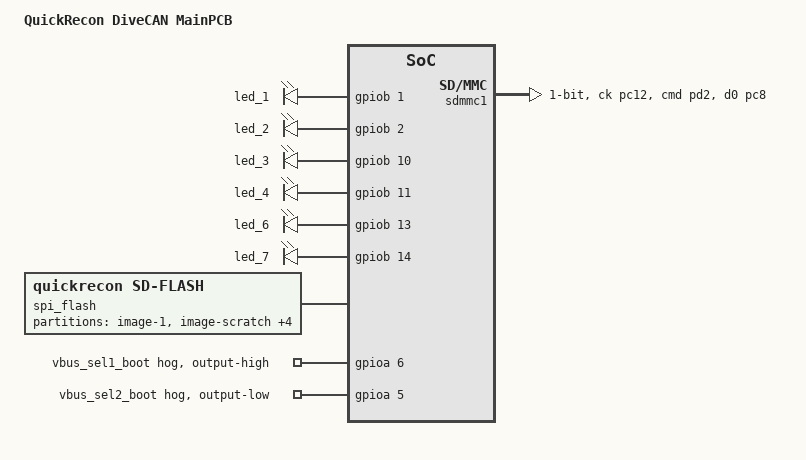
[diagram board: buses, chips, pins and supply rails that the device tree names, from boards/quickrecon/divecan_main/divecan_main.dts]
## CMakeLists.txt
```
cmake_minimum_required(VERSION 3.20.0)

set(DTS_ROOT ${CMAKE_CURRENT_SOURCE_DIR})

# Always-on GCC static analysis (-fanalyzer). Must be set before find_package(Zephyr).
# Analyzer false positives in CMSIS/HAL inline asm and Zephyr internals are demoted
# from -Werror to plain warnings; see COMPROMISE.md for the full list and rationale.
# Disabled on native_sim: host toolchain path doesn't populate GCC_COMPILER_VERSION
# before the SCA check runs, causing a false version-too-old error. Match the
# whole native_sim family (e.g. native_sim/native/64, required on aarch64 hosts),
# not just the bare "native_sim" string.
if(NOT BOARD MATCHES "native_sim")
    set(ZEPHYR_SCA_VARIANT gcc)
endif()
set(GCC_SCA_OPTS
    -Wno-error=analyzer-shift-count-overflow
    -Wno-error=analyzer-out-of-bounds
    -Wno-error=analyzer-null-dereference
    -Wno-error=analyzer-malloc-leak
    -Wno-error=analyzer-possible-null-dereference
    -Wno-error=analyzer-too-complex
    -Wno-error=analyzer-use-of-uninitialized-value
    -Wno-error=analyzer-infinite-loop
    -Wno-error=analyzer-deref-before-check
    -Wno-error=analyzer-allocation-size
    -Wno-error=analyzer-tainted-array-index
    -Wno-error=analyzer-tainted-offset
)

# Optional out-of-tree proprietary modules. Closed-source Zephyr modules that
# must never live in this tree are dropped into proprietary/<name>/ (git-ignored
# except the pointer doc — see proprietary/README.md). Any such module that
# supplies a zephyr/module.yml is discovered and wired in HERE (inside the app
# image's own CMakeLists, before its find_package) so it stays image-local: the
# MCUBoot child image runs its own find_package and never pulls it in. Never
# pass EXTRA_ZEPHYR_MODULES on the command line / env / cache — that would leak
# the module into the bootloader image.
#
# This is the generic hook retained for future proprietary subsystems. A module
# that a variant can *request* should follow the WANT_<FEATURE> / <FEATURE>
# Kconfig pattern (the variant sets CONFIG_WANT_<FEATURE>=y; the module defines
# the implementation symbol gated on its own devicetree node) and add its own
# "requested but unavailable" FATAL_ERROR check after find_package() below.
file(GLOB proprietary_module_manifests
     ${CMAKE_CURRENT_SOURCE_DIR}/proprietary/*/zephyr/module.yml)
foreach(module_manifest ${proprietary_module_manifests})
    get_filename_component(module_dir ${module_manifest} DIRECTORY) # .../<name>/zephyr
    get_filename_component(module_dir ${module_dir} DIRECTORY)      # .../<name>
    list(APPEND EXTRA_ZEPHYR_MODULES ${module_dir})
endforeach()

# The raw SD-to-flash adapter is shared by the application and MCUBoot on the
# DiveCAN MainPCB.  Keep it as a regular Zephyr module so each image gets the
# same flash semantics and devicetree binding; its Kconfig symbol remains off
# on boards without a quickrecon,sd-flash node.
list(APPEND EXTRA_ZEPHYR_MODULES
     ${CMAKE_CURRENT_SOURCE_DIR}/drivers/sd_flash)

# Required patches to the west-managed Zephyr tree, applied at configure time
# (idempotent, content-checked). The I2C patch backports the upstream STM32
# combined controller/target race handling to the pinned 4.4.1 release. The
# SPI-NOR fixes prevent wrong-address erases and unbounded WIP polling. A tree
# where a required patch is missing AND cannot be applied fails the build
# loudly. This runs before find_package so the sysbuild MCUBoot image also
# compiles the patched source.
set(_zephyr_tree "$ENV{ZEPHYR_BASE}")
if(NOT _zephyr_tree)
    execute_process(COMMAND west topdir
                    WORKING_DIRECTORY ${CMAKE_CURRENT_SOURCE_DIR}
                    OUTPUT_VARIABLE _west_topdir
                    OUTPUT_STRIP_TRAILING_WHITESPACE
                    RESULT_VARIABLE _west_rc ERROR_QUIET)
    if(_west_rc EQUAL 0)
        execute_process(COMMAND west config zephyr.base
                        WORKING_DIRECTORY ${CMAKE_CURRENT_SOURCE_DIR}
                        OUTPUT_VARIABLE _west_zephyr_base
                        OUTPUT_STRIP_TRAILING_WHITESPACE
                        RESULT_VARIABLE _west_base_rc ERROR_QUIET)
        if(_west_base_rc EQUAL 0)
            if(IS_ABSOLUTE "${_west_zephyr_base}")
                set(_zephyr_tree "${_west_zephyr_base}")
            else()
                set(_zephyr_tree "${_west_topdir}/${_west_zephyr_base}")
            endif()
        endif()
    endif()
endif()
if(_zephyr_tree AND EXISTS "${_zephyr_tree}/drivers/i2c/i2c_stm32_v2.c")
    file(READ "${_zephyr_tree}/drivers/i2c/i2c_stm32_v2.c" _i2c_stm32_src)
    string(FIND "${_i2c_stm32_src}"
           "i2c_stm32_target_preempt_controller_event" _i2c_race_marker)
    if(_i2c_race_marker EQUAL -1)
        set(_i2c_race_patch
            ${CMAKE_CURRENT_SOURCE_DIR}/patches/zephyr-i2c-stm32-controller-target-race.patch)
        execute_process(COMMAND git -C "${_zephyr_tree}" apply "${_i2c_race_patch}"
                        RESULT_VARIABLE _i2c_patch_rc
                        ERROR_VARIABLE _i2c_patch_err)
        if(NOT _i2c_patch_rc EQUAL 0)
            message(FATAL_ERROR
                "Zephyr STM32 I2C controller/target race patch is NOT applied "
                "and auto-apply failed (${_i2c_patch_err}). Building without "
                "it can route an own-address match through controller handling "
                "and panic in i2c_stm32_target_event(). Apply "
                "${_i2c_race_patch} to ${_zephyr_tree} (rebase it if the "
                "Zephyr revision changed).")
        endif()
        message(STATUS
            "Applied Zephyr STM32 I2C controller/target race patch to ${_zephyr_tree}")
    endif()
elseif(NOT BOARD MATCHES "native_sim")
    message(WARNING "Could not locate the Zephyr STM32 I2C driver to verify "
                    "the required controller/target race patch — do not ship "
                    "this build unverified.")
endif()

if(_zephyr_tree AND EXISTS "${_zephyr_tree}/drivers/flash/spi_nor.c")
    file(READ "${_zephyr_tree}/drivers/flash/spi_nor.c" _spi_nor_src)
    string(FIND "${_spi_nor_src}" "spi_nor_erase_opcode_4b" _patch_marker)
    if(_patch_marker EQUAL -1)
        set(_spi_nor_patch
            ${CMAKE_CURRENT_SOURCE_DIR}/patches/zephyr-spi-nor-4byte-erase-opcode.patch)
        execute_process(COMMAND git -C "${_zephyr_tree}" apply "${_spi_nor_patch}"
                        RESULT_VARIABLE _patch_rc ERROR_VARIABLE _patch_err)
        if(NOT _patch_rc EQUAL 0)
            message(FATAL_ERROR
                "zephyr spi_nor 4-byte erase-opcode patch is NOT applied and "
                "auto-apply failed (${_patch_err}). Building without it produces "
                "firmware that erases the wrong NOR locations. Apply "
                "${_spi_nor_patch} to ${_zephyr_tree} (rebase it if the zephyr "
                "revision changed).")
        endif()
        message(STATUS "Applied zephyr spi_nor 4-byte erase-opcode patch to ${_zephyr_tree}")
    endif()
    # Second patch: bound the WIP status poll with a timeout. Without it a
    # transient SPI glitch that leaves the status stuck WIP=1 busy-spins forever
    # and the IWDG resets the MCU mid erase/program (0xF278 mass erase never
    # reaches NVS; factory restore leaves slot1 incomplete). Re-read the source —
    # the 4-byte patch above may have just modified it.
    file(READ "${_zephyr_tree}/drivers/flash/spi_nor.c" _spi_nor_src2)
    string(FIND "${_spi_nor_src2}" "wip_deadline" _wip_marker)
    if(_wip_marker EQUAL -1)
        set(_wip_patch
            ${CMAKE_CURRENT_SOURCE_DIR}/patches/zephyr-spi-nor-wip-timeout.patch)
        execute_process(COMMAND git -C "${_zephyr_tree}" apply "${_wip_patch}"
                        RESULT_VARIABLE _wip_rc ERROR_VARIABLE _wip_err)
        if(NOT _wip_rc EQUAL 0)
            message(FATAL_ERROR
                "zephyr spi_nor WIP-poll timeout patch is NOT applied and "
                "auto-apply failed (${_wip_err}). Without it a stuck SPI-NOR "
                "status poll hangs until the IWDG resets the MCU mid "
                "erase/program. Apply ${_wip_patch} to ${_zephyr_tree} (rebase "
                "it if the zephyr revision changed).")
        endif()
        message(STATUS "Applied zephyr spi_nor WIP-poll timeout patch to ${_zephyr_tree}")
    endif()

elseif(NOT BOARD MATCHES "native_sim")
    message(WARNING "Could not locate the Zephyr tree to verify required "
                    "SPI-NOR patches — do not ship this build unverified.")
endif()

if(_zephyr_tree AND EXISTS "${_zephyr_tree}/subsys/fs/fcb/fcb.c")
    file(READ "${_zephyr_tree}/include/zephyr/fs/fcb.h" _fcb_hdr)
    string(FIND "${_fcb_hdr}" "FCB_FLAGS_INIT_SKIP_WALK" _fcb_marker)
    if(_fcb_marker EQUAL -1)
        set(_fcb_patch
            ${CMAKE_CURRENT_SOURCE_DIR}/patches/zephyr-fcb-init-skip-entry-walk.patch)
        execute_process(COMMAND git -C "${_zephyr_tree}" apply "${_fcb_patch}"
                        RESULT_VARIABLE _fcb_rc ERROR_VARIABLE _fcb_err)
        if(NOT _fcb_rc EQUAL 0)
            message(FATAL_ERROR
                "Zephyr FCB init-skip-walk patch is NOT applied and auto-apply "
                "failed (${_fcb_err}). Without it the flash-log FCB mount does "
                "thousands of tiny SPI reads at boot, scaling boot time with "
                "log depth. Apply ${_fcb_patch} to ${_zephyr_tree}.")
        endif()
        message(STATUS "Applied Zephyr FCB init-skip-walk patch to ${_zephyr_tree}")
    endif()
endif()

if(_zephyr_tree AND EXISTS "${_zephyr_tree}/subsys/kvss/nvs/nvs_priv.h")
    file(READ "${_zephyr_tree}/subsys/kvss/nvs/nvs_priv.h" _nvs_hdr)
    string(FIND "${_nvs_hdr}" "#ifndef NVS_BLOCK_SIZE" _nvs_marker)
    if(_nvs_marker EQUAL -1)
        set(_nvs_patch
            ${CMAKE_CURRENT_SOURCE_DIR}/patches/zephyr-nvs-block-size-override.patch)
        execute_process(COMMAND git -C "${_zephyr_tree}" apply "${_nvs_patch}"
                        RESULT_VARIABLE _nvs_rc ERROR_VARIABLE _nvs_err)
        if(NOT _nvs_rc EQUAL 0)
            message(FATAL_ERROR
                "Zephyr NVS block-size override patch is NOT applied and "
                "auto-apply failed (${_nvs_err}). Without it the NVS sector "
                "scans read 32 bytes per SPI transaction at boot. Apply "
                "${_nvs_patch} to ${_zephyr_tree}.")
        endif()
        message(STATUS "Applied Zephyr NVS block-size override patch to ${_zephyr_tree}")
    endif()
endif()

find_package(Zephyr REQUIRED HINTS $ENV{ZEPHYR_BASE})
project(divecan_firmware)

# Widen the NVS read/compare granule (default 32 B) so the boot-time sector
# scans over external SPI NOR amortise the per-transaction SPI framework
# overhead (32 reads per 4 KiB sector check instead of 128). Stack cost: one
# NVS_BLOCK_SIZE buffer per NVS read/compare/write frame (+96 B vs the 32 B
# default) on every NVS caller — main, divecan_rx (UDS settings saves), and
# the system workqueue (error-histogram periodic save). 256 was tried and
# CRASHED both settings-heavy HIL tests with STACK_CHK_FAIL on divecan_rx /
# sysworkq (run 31187089880); 128 halves the pressure and those two stacks
# also gained +256 B headroom each. Requires the nvs_priv.h #ifndef guard
# patch above.
zephyr_compile_definitions(NVS_BLOCK_SIZE=128)

target_sources(app PRIVATE
    src/main.c
    src/errors.c
    src/boot_history.c
    src/runtime_settings.c
    src/oxygen_cell_math.c
    src/oxygen_cell_channels.c
    src/consensus_subscriber.c
    src/calibration.c
    src/calibration_store.c
    src/hw_version.c
    src/power_math.c
    src/power_management.c
    src/heartbeat.c
    src/i2c_bus_lock.c
    src/external_flash.c
    src/storage_work_queue.c
    src/error_histogram.c
    src/firmware_confirm.c
    src/flash_mass_erase.c
    src/maintenance_arena.c
    src/device_current.c
)
target_sources_ifdef(CONFIG_ALARM app PRIVATE src/alarm.c)
target_sources_ifdef(CONFIG_POSEIDON_ACCESSORIES app PRIVATE
    src/poseidon_accessories.c)
# The paced thread-analyzer wrapper calls thread_analyzer_run(), which
# Zephyr only provides when CONFIG_THREAD_ANALYZER=y. That symbol has
# `depends on !ARCH_POSIX`, so on native_sim it is unavailable and the
# source must not be compiled. Guard accordingly.
target_sources_ifdef(CONFIG_THREAD_ANALYZER app PRIVATE
    src/thread_analyzer_paced.c)
target_sources_ifdef(CONFIG_FACTORY_IMAGE app PRIVATE src/factory_image.c)
target_sources_ifdef(CONFIG_FACTORY_IMAGE_BACKEND_FLASH app PRIVATE
    src/factory_image_backend_flash.c)
target_sources_ifdef(CONFIG_DIVECAN_OPTION_BYTES_CHECK app PRIVATE
    src/option_bytes.c)
target_sources_ifdef(CONFIG_DIVECAN_WATCHDOG app PRIVATE src/watchdog_feeder.c)
target_sources_ifdef(CONFIG_HAS_ANALOG_CELL app PRIVATE src/oxygen_cell_analog.c)
target_sources_ifdef(CONFIG_HAS_PRESSURE_TRANSDUCER app PRIVATE
    src/tank_pressure.c
    src/tank_pressure_math.c)
target_sources_ifdef(CONFIG_HAS_DIVEO2_CELL app PRIVATE src/oxygen_cell_diveo2.c)
target_sources_ifdef(CONFIG_HAS_O2S_CELL app PRIVATE src/oxygen_cell_o2s.c)

# PPO2 PID controller + solenoid fire timing — pure math is always built so
# UDS state-DID handlers can call ppo2_control_get_snapshot() unconditionally,
# but the threaded controller is only compiled in when a physical O2
# injection solenoid is present on the variant.
target_sources(app PRIVATE src/ppo2_control_math.c src/ppo2_control.c)
# PID autotune — always built (pure math + stubs); the threaded routine and its
# thread are gated on CONFIG_HAS_O2_SOLENOID inside the TU. Autotune ships with
# PID (no separate Kconfig): wherever PID control exists, autotune exists.
target_sources(app PRIVATE src/ppo2_autotune_math.c src/ppo2_autotune.c)
target_include_directories(app PRIVATE include)

# DiveCAN protocol + UDS/ISO-TP
target_sources(app PRIVATE
    src/divecan/divecan_channels.c
    src/divecan/divecan_send.c
    src/divecan/divecan_tx.c
    src/divecan/isotp.c
    src/divecan/isotp_tx_queue.c
    src/divecan/divecan_rx.c
    src/divecan/divecan_ppo2_math.c
    src/divecan/divecan_ppo2_tx.c
    src/divecan/uds/uds.c
    src/divecan/uds/uds_ota.c
    src/divecan/uds/uds_state_did.c
    src/divecan/uds/uds_settings.c
    src/divecan/uds/uds_log_push.c
)
# UDS log push as a Zephyr log backend (live RTT-over-UDS streaming).
# Depends on the flash log subsystem for the shared severity threshold
# accessor — the two backends together give us "persistent log on flash
# + live tail over UDS" with one runtime control DID.
target_sources_ifdef(CONFIG_FLASH_LOG app PRIVATE
    src/divecan/uds/uds_log_push_backend.c
)
target_include_directories(app PRIVATE src/divecan/include)
target_include_directories(app PRIVATE src)

# Flash log subsystem — two FCB instances, single writer thread,
# zbus listeners + RTT capture backend + UDS download path.
target_sources_ifdef(CONFIG_FLASH_LOG app PRIVATE
    src/flash_log/flash_log.c
    src/flash_log/flash_log_fastseek.c
    src/flash_log/flash_log_listeners.c
    src/flash_log/flash_log_backend.c
    src/flash_log/flash_log_index.c
    src/flash_log/flash_log_reader.c
    src/divecan/uds/uds_log_download.c
)
target_include_directories(app PRIVATE src/flash_log)

add_subdirectory(drivers/solenoid)
add_subdirectory(drivers/ads1x1x)
add_subdirectory_ifdef(CONFIG_GPIO_SIM drivers/gpio_sim)

# Build-time version string. We pass it in as an already-quoted string literal
# so the C code never has to stringify a token (avoids SonarCloud S958/S959/
# S960/S967/S968/M23_042/M23_212 firings on a STRINGIFY macro chain).
# Prefer `git describe`; fall back to "dev" outside a git checkout.
execute_process(
    COMMAND git -C ${CMAKE_CURRENT_SOURCE_DIR} describe --tags --always --dirty
    OUTPUT_VARIABLE APP_BUILD_VERSION_RAW
    OUTPUT_STRIP_TRAILING_WHITESPACE
    ERROR_QUIET
    RESULT_VARIABLE APP_BUILD_VERSION_RC
)
if(NOT APP_BUILD_VERSION_RC EQUAL 0 OR APP_BUILD_VERSION_RAW STREQUAL "")
    set(APP_BUILD_VERSION_RAW "dev")
endif()
target_compile_definitions(app PRIVATE
    APP_BUILD_VERSION_STR="${APP_BUILD_VERSION_RAW}"
)

# Keep a full commit identity for manifests and release provenance. git describe
# is intentionally shorter/human-facing and remains the firmware UI string.
execute_process(
    COMMAND git -C ${CMAKE_CURRENT_SOURCE_DIR} rev-parse HEAD
    OUTPUT_VARIABLE APP_BUILD_COMMIT_RAW
    OUTPUT_STRIP_TRAILING_WHITESPACE
    ERROR_QUIET
    RESULT_VARIABLE APP_BUILD_COMMIT_RC
)
if(NOT APP_BUILD_COMMIT_RC EQUAL 0 OR APP_BUILD_COMMIT_RAW STREQUAL "")
    set(APP_BUILD_COMMIT_RAW "${APP_BUILD_VERSION_RAW}")
endif()

# VERSION is the product release number and the source for MCUboot's image
# header version. Keep the independently-derived git identity above as the
# exact source revision. Both are emitted into test_manifest.json so HIL and
# release packaging can prove which numbered image and commit they exercised.
if(NOT DEFINED APP_VERSION_STRING OR APP_VERSION_STRING STREQUAL "")
    set(APP_RELEASE_VERSION_RAW "0.0.0")
else()
    set(APP_RELEASE_VERSION_RAW "${APP_VERSION_STRING}")
endif()

# Build-time variant string, derived from the selected variant conf
# (-DEXTRA_CONF_FILE=variants/<Name>.conf). Baked into the binary (served over
# UDS DID 0xF002) AND written into test_manifest.json below, both from this one
# value, so the HIL rig can assert the flashed variant matches the manifest it
# is qualifying against. Falls back to "dev" when no variant conf is selected.
set(APP_BUILD_VARIANT_RAW "dev")
if(DEFINED EXTRA_CONF_FILE AND EXTRA_CONF_FILE MATCHES "variants/([^/;]+)\\.conf")
    set(APP_BUILD_VARIANT_RAW "${CMAKE_MATCH_1}")
endif()
target_compile_definitions(app PRIVATE
    APP_BUILD_VARIANT_STR="${APP_BUILD_VARIANT_RAW}"
)

# App-only hardening flags (not applied to Zephyr kernel/drivers).
#
# Scope: this is an open-source, deliberately-hackable platform — there
# is no adversary, no secrets to protect, no fault-injection threat
# model. The only attack surface that matters is the one that exists
# anyway: software bugs, buffer overflows, uninitialised reads. We
# harden against those and ignore the rest.
#
# What's enabled:
#   -ftrivial-auto-var-init=pattern   catches uninit-read bugs by
#                                     filling locals with 0xAA
#   _FORTIFY_SOURCE=2 (via Kconfig)   runtime bounds checks on libc
#                                     string/mem ops when the dest
#                                     size is compile-time known
#   stack canaries (via Kconfig)      catch return-address smashing
#                                     from buffer overflows
#   -Wstack-usage=1305                static cap on per-function stack
#
# What's deliberately NOT enabled:
#   -fstack-clash-protection          mitigates unbounded stack growth
#                                     attack — architecturally impossible
#                                     here per NASA P10 (no recursion,
#                                     no VLAs, all loops fixed-bound)
#   -fharden-compares                 fault-injection defence — out of
#                                     scope per platform philosophy
#   -fharden-conditional-branches     same as above
#
target_compile_options(app PRIVATE
    -Wall
    -Wextra
    -Wwrite-strings
    -Wreturn-type
    -Wno-unused-parameter
    -Wno-vla
    -ftrivial-auto-var-init=pattern
    -fstack-usage
    -std=gnu23
)
target_cc_option(app PRIVATE -Wstack-usage=1305)

# Integration test shim (native_sim only)
target_sources_ifdef(CONFIG_INTEGRATION_TEST_SHIM app PRIVATE
    tests/integration/src/test_shim.c
    tests/integration/src/test_shim_uart.c
    tests/integration/src/test_shim_adc.c
    tests/integration/src/test_shim_gpio.c
    tests/integration/src/test_shim_shared.c
)
# Host-side adapter — compiled into the native_simulator runner so it
# can use raw Linux/glibc headers without colliding with Zephyr's POSIX
# shims.  Provides shared memory wrappers.
if(CONFIG_INTEGRATION_TEST_SHIM)
    target_sources(native_simulator INTERFACE
        ${CMAKE_CURRENT_SOURCE_DIR}/tests/integration/src/test_shim_socket_adapt.c)
    target_link_options(native_simulator INTERFACE "-lrt")
endif()

# --- HIL test manifest -------------------------------------------------------
# Emit a machine-readable description of this binary's compile-time config
# (cells/power/solenoids/control + CAN bitrate) so the test rig (divecan_rig)
# can self-configure and select the tests relevant to the flashed binary.
# Reads the resolved Kconfig (.config) + devicetree; both exist by build time.
add_custom_command(
    TARGET app POST_BUILD
    COMMAND ${PYTHON_EXECUTABLE}
            ${CMAKE_CURRENT_SOURCE_DIR}/scripts/gen_test_manifest.py
            --config ${CMAKE_BINARY_DIR}/zephyr/.config
            --dt-header ${CMAKE_BINARY_DIR}/zephyr/include/generated/zephyr/devicetree_generated.h
            --variant ${APP_BUILD_VARIANT_RAW}
            --version ${APP_RELEASE_VERSION_RAW}
            --commit ${APP_BUILD_COMMIT_RAW}
            --out ${CMAKE_BINARY_DIR}/zephyr/test_manifest.json
    BYPRODUCTS ${CMAKE_BINARY_DIR}/zephyr/test_manifest.json
    COMMENT "Emitting HIL test_manifest.json from resolved Kconfig + devicetree"
    VERBATIM
)
```

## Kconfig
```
mainmenu "DiveCAN Firmware"

rsource "drivers/solenoid/Kconfig"
rsource "drivers/ads1x1x/Kconfig"
rsource "src/Kconfig"

source "Kconfig.zephyr"
```

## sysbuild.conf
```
# Sysbuild configuration for DiveCAN firmware with MCUBoot.
#
# See ARCHITECTURE.md and the OTA plan for design rationale. Key
# choices captured here:
#
# - MCUBoot is the bootloader (slot0 = internal flash 220 KiB;
#   slot1 + scratch + factory use the board's external flash-compatible
#   device: SPI NOR on Jr, raw SD on MainPCB).
# - Swap-using-scratch — the scratch partition gives clean failure
#   isolation: slot0 is untouched until each swap step completes.
#   Higher write amplification than swap-using-move but easier to
#   reason about under power loss.
# - No private-key signing. SHA-256 integrity only. This is an open
#   platform — anyone can build and flash without holding a signing
#   key. Per-image hash verification (`bootutil_img_validate`) still
#   catches corruption pre-swap.

SB_CONFIG_BOOTLOADER_MCUBOOT=y
SB_CONFIG_MCUBOOT_MODE_SWAP_SCRATCH=y
SB_CONFIG_BOOT_SIGNATURE_TYPE_NONE=y
SB_CONFIG_BOOT_SIGNATURE_KEY_FILE=""

# Emit a single merged.hex containing bootloader + signed app for
# convenient `west flash` / probe-rs / openocd flashing.
SB_CONFIG_MERGED_HEX_FILES=y
```

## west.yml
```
manifest:
  remotes:
    - name: zephyrproject-rtos
      url-base: https://github.com/zephyrproject-rtos

  projects:
    - name: zephyr
      remote: zephyrproject-rtos
      # Pinned to the Zephyr 4.4.1 release revision so CI
      # analyzes exactly what local builds and HIL testing run against.
      # Bump deliberately: update the local checkout, re-run the native +
      # HIL suites, then move this pin to match.
      revision: 1f6485eca25431b5ff27ce9a754218c9e559bbbb
      # Keep west-managed repositories out of the application repository's
      # visible top-level tree. The prefix applies to Zephyr itself and every
      # project imported by Zephyr's manifest (modules, MCUboot, tools, etc.).
      # Changing it requires pristine builds because CMake caches these paths.
      import:
        path-prefix: .west-projects

  self:
    path: app
```

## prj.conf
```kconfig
CONFIG_PRINTK=y
CONFIG_GPIO=y
CONFIG_CONSOLE=y
CONFIG_USE_SEGGER_RTT=y
CONFIG_RTT_CONSOLE=y

# Hardening (applied globally — Zephyr + app)
# Entropy/RNG disabled — entropy_stm32_rng_init asserts during init on Jr
# hardware (PC=assert_post_action, LR=entropy_stm32.c:862, reason=
# K_ERR_KERNEL_PANIC). Just commenting out CONFIG_ENTROPY_GENERATOR is
# NOT enough: the STM32 RNG driver's Kconfig auto-enables when the DT
# rng node is "okay", which selects ENTROPY_HAS_DRIVER which pulls in
# ENTROPY_GENERATOR. The override below forces the driver off so the
# init function never runs. Root cause is likely PLL Q clock config
# for CLK48 mux — leaves the RNG without a clock, dev->data deref
# faults. TODO: revisit clock setup so we can re-enable HW entropy.
# CONFIG_ENTROPY_GENERATOR=y
CONFIG_ENTROPY_STM32_RNG=n
CONFIG_FORTIFY_SOURCE_RUN_TIME=y
CONFIG_HW_STACK_PROTECTION=y
CONFIG_COMPILER_WARNINGS_AS_ERRORS=y
CONFIG_OVERRIDE_FRAME_POINTER_DEFAULT=y

# Stack canaries — guard word at the bottom of every function's stack
# frame, checked at epilogue. Catches return-address smashing from
# buffer overflows (the dominant software-bug failure mode in C). The
# _STRONG variant covers any function with a local array OR taking
# the address of a local, which is what we want — bog-standard
# _REGULAR only protects functions with char buffers ≥8 bytes and
# misses most real overflow targets. Canary seed comes from a build-
# time random word via the SDK; not cryptographically strong but the
# threat model here is software bugs, not adversarial bypass.
CONFIG_STACK_CANARIES=y
CONFIG_STACK_CANARIES_STRONG=y

# Hardware FPU — DELIBERATELY OFF, measured 2026-07. The M4F single-precision
# FPU looks free but is not: safe multi-thread FP requires CONFIG_FPU_SHARING
# (float math runs in PID, consensus, cell, and cal threads), and on this
# build that costs ~3.2 KB of RAM — 64 B of callee-saved FP context appended
# to every struct k_thread (~22 threads) plus the MPU stack guard widening
# from 32 B to 128 B per stack for lazy-stacking overlap. The Poseidon build
# sits at ~99.8% RAM, so enabling it overflowed the region by 3,184 B for a
# ~2.5 KB FLASH saving (single-precision softfloat elimination). Softfloat
# single is fast enough for the 100 ms control cadence. REVISIT if the
# thread count drops substantially (consolidation shrinks the per-thread
# tax) or if RAM headroom appears.
# CONFIG_FPU=y
# CONFIG_FPU_SHARING=y

# Link-time optimization — REJECTED 2026-07 on HIL A/B evidence, despite a
# −21.6 KB (−11%) app-image saving. With CONFIG_LTO=y (+
# CONFIG_ISR_TABLES_LOCAL_DECLARATION=y) the DUT reproducibly failed
# test_dut_services.py::test_factory_default_battery_threshold_matches_manifest:
# after the NVS-erase DID (0xF279) warm reboot the head came back NOT
# broadcasting PPO2 (UDS still answered; a cold power cycle recovered it).
# 3/3 fail with LTO, 3/3 pass on the byte-identical source tree without
# LTO, 3/3 pass on the pre-change baseline. Root cause not isolated (LTO
# inlining/reordering exposing a latent init race, or a miscompile) — an
# unexplained behavioral delta is disqualifying on a life-support device.
# Re-attempt only WITH a root cause. Repro: seed a non-default battery
# setting, programming session, write 0xF279=0x01, wait for the PPO2
# broadcast to resume (it doesn't). If re-attempted, remember: size(1)
# misreports LTO rodata as `data` (use the linker region table) and
# -fstack-usage/.su static WCS numbers degrade under LTO.
# CONFIG_LTO=y
# CONFIG_ISR_TABLES_LOCAL_DECLARATION=y

# Main thread stack — kept at 2048 after a 1024 trim caused a
# K_ERR_STACK_CHK_FAIL canary trip on real hardware. Static WCS came
# back "unbounded" for main because settings/MCUBoot/SPI inits hit
# function-pointer call paths the analyzer can't trace; runtime
# evidence is the only reliable bound. Revisit only with INIT_STACKS
# high-water-mark data from a real boot.
CONFIG_MAIN_STACK_SIZE=2048

# Assertions (kept in production — controlled reboot over undefined behavior)
CONFIG_ASSERT=y
CONFIG_ASSERT_VERBOSE=y

# Printf/cbprintf size trims — app code has no %lld/%llu and no
# LOG_DBG callsites (verified via grep), so the FULL_INTEGRAL formatter
# table and the function-name prefix infrastructure are dead weight in
# this binary. Switching to REDUCED_INTEGRAL keeps %d/%u/%x/%s/%c/%p
# but drops the long-long path. PICOLIBC_IO_LONG_LONG mirrors the same
# trim on the picolibc side for stdio.
# Saves ~1-2 KB FLASH each. Revisit if any new LOG_x site needs %lld.
CONFIG_CBPRINTF_FULL_INTEGRAL=n
CONFIG_CBPRINTF_REDUCED_INTEGRAL=y
CONFIG_PICOLIBC_IO_LONG_LONG=n
CONFIG_LOG_FUNC_NAME_PREFIX_DBG=n

# Logging — deferred mode. Buffer reduced from 2 KB to 1 KB to free
# RAM; the processing thread runs at high priority (3) so the buffer
# drains quickly and a smaller staging area is fine for the bursts
# we actually see. Watch dropped_cnt in the RTT log_core stats — if
# it climbs noticeably under real workloads, bump back to 2048.
CONFIG_LOG=y
CONFIG_LOG_BUFFER_SIZE=1024
CONFIG_LOG_PROCESS_THREAD_PRIORITY=3
# RTT up-buffer at 2 KB. Both MCUBoot and this app place
# SEGGER_RTT_SECTION_CUSTOM at RAM base, then lay it out as
# _acUpBuffer + _acDownBuffer + _SEGGER_RTT. The buffer size must
# match between binaries or the control block ends up at different
# addresses — openocd attaches to whichever address it finds first
# (MCUBoot's, since its address is lower) and stays locked there
# after MCUBoot chainloads, so the app's logs vanish into a control
# block that openocd never reads. sysbuild/mcuboot.conf carries a
# matching CONFIG_SEGGER_RTT_BUFFER_SIZE_UP=2048 to keep both
# binaries' _SEGGER_RTT at the same address. Reduced from 4 KB to
# 4 KB to accommodate the boot-time preamble burst (~1.5 KB of
# `emit_startup_preamble` in src/main.c) on top of the regular
# pre-main and pre-host-attach LOG output (~1 KB of MCUBoot + early
# init lines). At 2 KB the preamble was being trimmed from the
# up-buffer before openocd could drain it, even with 50 ms per-line
# pacing. Verified against chip RTT capture. Costs +2 KB RAM (RTT
# section is in noinit; doesn't grow .bss). Must match
# sysbuild/mcuboot.conf so MCUBoot and app's _SEGGER_RTT control
# block end up at the same RAM address (see comment above).
CONFIG_SEGGER_RTT_BUFFER_SIZE_UP=4096

# Reboot
CONFIG_REBOOT=y

# IPC (zbus for decoupled inter-module communication)
CONFIG_ZBUS=y
CONFIG_ZBUS_MSG_SUBSCRIBER=y

# State Machine Framework — flat-only, no hierarchical / initial-transition support.
# See docs/STATE_MACHINES.md for the modules that use it.
CONFIG_SMF=y
# CONFIG_SMF_ANCESTOR_SUPPORT is not set
# CONFIG_SMF_INITIAL_TRANSITION is not set

# ---- MCUBoot + OTA support ----
# Build app as an MCUBoot-compatible image (slot0). Sysbuild also
# pulls in the bootloader as a child image — see sysbuild.conf and
# sysbuild/mcuboot.conf.
CONFIG_BOOTLOADER_MCUBOOT=y

# Bootutil library — exposes boot_swap_type, boot_read_bank_header,
# bootutil_img_validate to the application so it can interrogate
# MCUBoot state and pre-validate slot1 before triggering activation.
CONFIG_MCUBOOT_BOOTUTIL_LIB=y

# Image manager API — boot_request_upgrade, boot_write_img_confirmed,
# boot_is_img_confirmed.
CONFIG_MCUBOOT_IMG_MANAGER=y
CONFIG_IMG_MANAGER=y

# Buffered flash writer for the OTA RX path. This is a write-coalescing
# buffer, NOT an erase buffer — flash_img_buffered_write() accumulates
# incoming UDS payload bytes and flushes when full. Sector erase is
# handled internally by the DFU subsystem at sector boundaries based on
# the running write offset, independent of the buffer size. Only
# constraint: must be >= the flash write block size. 1024 amortises the
# external-device transaction overhead while costing only 1 KB of RAM vs. the
# previous 4 KB.
CONFIG_IMG_BLOCK_BUF_SIZE=1024
CONFIG_STREAM_FLASH=y
CONFIG_FLASH_MAP=y

# SHA-256 walk over a flash area — used by the UDS-OTA pre-activation
# pipeline to verify slot1 matches the SHA-256 TLV embedded in the
# image trailer before boot_request_upgrade() is allowed to run.
CONFIG_IMG_ENABLE_IMAGE_CHECK=y

# ---- Analog oxygen cells (external ADS1115 ADCs) ----
# Use the board-local multi-channel ADS1X1X driver (drivers/ads1x1x) instead of
# the upstream single-channel one. The upstream driver only supports channel_id
# 0, so a second analog cell sharing one ADS1115 (e.g. AIN2-AIN3) silently never
# reads. The fork stores per-channel MUX config and programs it per conversion.
# Disable the in-tree driver so only one instantiates the ti,ads1115 nodes.
CONFIG_ADC=y
CONFIG_ADC_ADS1X1X=n
CONFIG_ADC_ADS1X1X_LOCAL=y

# ---- Settings + NVS on external storage ----
# Storage partition (label "storage") lives at the top of the board's
# 64 MB external flash device — SPI NOR on Jr or raw SD on MainPCB.
# Zephyr's settings subsystem discovers it through storage_partition.
CONFIG_FLASH=y
CONFIG_SETTINGS=y
CONFIG_SETTINGS_NVS=y
CONFIG_NVS=y

# The board flash driver must expose 4 KB logical erase pages so the 32 KB
# settings partition mounts as eight NVS sectors. Jr configures this through
# SPI_NOR_FLASH_LAYOUT_PAGE_SIZE; the MainPCB SD wrapper declares the same
# geometry in devicetree.

# Factory-image copy chunk size — read/write loop only, not erase-related.
# 1 KB gives 220 loop iterations across the 220 KB slot at ~hundreds of
# microseconds per SPI read+write; the watchdog feeds inside the loop.
# Was 4 KB by default; the "matches sector erase" rationale in the
# original Kconfig help is wrong — the bulk erase happens before the
# copy loop starts.
CONFIG_FACTORY_IMAGE_CHUNK_SIZE=1024

# ---- Flash log (FCB-based dive log) ----
# Two parallel FCB instances on external flash — telemetry FCB
# for structured records and text FCB for LOG_x capture. Each
# declares 100 × 64 KiB logical sectors (block-erase). See
# docs/FLASH_LOG.md and src/flash_log/.
CONFIG_FLASH_LOG=y
CONFIG_FCB=y
CONFIG_FCB_ALLOW_FIXED_ENDMARKER=y
# Used to stamp reset_cause in the BOOT_MARKER entry
CONFIG_HWINFO=y

# ---- Thread stack instrumentation (belt and braces) ----
# Two complementary tools share one goal — keeping stack budgets honest:
#   - Static: scripts/stack_analysis.sh walks .su + RTL dumps to compute
#     worst-case stack per function (upper bounds, derived at build time).
#   - Runtime: INIT_STACKS fills each stack with a sentinel pattern at spawn
#     time so targeted high-water-mark builds can count untouched bytes.
# The always-on paced thread analyzer was removed from production builds to
# fund the UDS RX stack margin found necessary by HIL crash-injection testing.
# Re-enable only in a temporary measurement build.
# CONFIG_THREAD_ANALYZER is not set
# CONFIG_THREAD_ANALYZER_USE_LOG is not set
# AUTO mode disabled — its tight emission loop floods 40+ LOG_INF
# back-to-back from a single thread tick, overflowing the 1 KB
# deferred log buffer (LOG_MODE_OVERFLOW=y evicts oldest, so the
# first half of the dump disappears). We run our own paced wrapper
# in src/thread_analyzer_paced.c that calls thread_analyzer_run()
# with a callback that LOG_INFs one thread, k_msleeps 50 ms to let
# the log subsystem drain, then proceeds. Same output, no drops.
# CONFIG_THREAD_ANALYZER_AUTO is not set
# Analyzer auto mode remains disabled; use src/thread_analyzer_paced.c only in
# deliberate measurement builds where CONFIG_THREAD_ANALYZER is re-enabled.
# CONFIG_THREAD_ANALYZER_AUTO_STACK_SIZE is not set
CONFIG_INIT_STACKS=y
CONFIG_THREAD_NAME=y
CONFIG_THREAD_STACK_INFO=y

# scripts/wcs.py static-WCS for fl_writer is ~336 B but the RUNTIME high-water was
# ~944-984 B (thread_analyzer / check_high_water) — the static tool under-counts the
# FCB/flash/spi_nor call depth, and the two ~100 B header+payload coalescing buffers
# (fl_write_entry_to_fcb + fl_write_telemetry_batch Pass B) used to sit on this stack,
# BOTH live at once on the Pass-1 chain (~200 B). Those are now a single shared static
# (fl_writer_scratch, 108 B) — the writer is the only thread on the FCB path and the
# passes run sequentially, so it is safe. -fstack-usage confirms the deepest chain
# dropped ~200 B (fl_batch_flush 216->112, fl_write_entry_to_fcb 168->72); since the
# flash/SPI tail is unchanged the runtime high-water drops by the same ~200 B, i.e.
# to ~760-790 B. Audited: NO unbounded items (no alloca/VLA/recursion). Kept at 1024
# (NOT reduced) on purpose: the rare fcb_rotate()/256 KiB sector-erase path is deeper
# than the normal-append sample and remains UNMEASURED, so 1024 preserves a strict
# margin gain on every path (~234 B normal, +200 B vs before on rotation) rather than
# trading it away. (NOT the #5 crash — that was cal_thread, see calibration.c.)
# Open validation: re-run scripts/check_high_water.py on hardware, ideally forcing a
# ring wrap, before reducing this. RAM cost of the static: +64 B (AP 144->80 B free).
CONFIG_FLASH_LOG_WRITER_STACK=1024

# ---- LPTIM kernel timebase (see divecan_jr.dts stm32_lp_tick_source) ----
# CONFIG_PM is required by STM32_LPTIM_TIMER. The board DTS deletes
# cpu-power-states, so PM never enters STOP on idle (WFI only): SWD stays
# attached and the CAN peripheral keeps receiving. LPTIM on LSI decouples
# kernel time from HCLK so boot_clock_boost() can switch SYSCLK safely.
CONFIG_PM=y

# The error-histogram periodic save runs NVS writes on the system workqueue;
# with the widened NVS_BLOCK_SIZE stack buffers the default 1024 B is too
# tight (STACK_CHK_FAIL family, run 31187089880). +256 B headroom.
CONFIG_SYSTEM_WORKQUEUE_STACK_SIZE=1280

# NVS lookup cache. Without it, settings_save_one() linearly scans the storage
# partition on every write: BENCH-MEASURED 8.4-8.6 s for the first write of a key
# after boot (reproducible across boots) and ~1.0-1.6 s steady-state, during which
# the head transmits NOTHING on DiveCAN -- PPO2 broadcasts included. With the cache
# the same writes cost 6-9 ms. Size matters and was measured, not guessed: 64 gives
# ~7 ms while 32 and 16 both sit at ~1.0 s, so do not shrink this to reclaim RAM
# without re-measuring.
CONFIG_NVS_LOOKUP_CACHE=y
CONFIG_NVS_LOOKUP_CACHE_SIZE=64

# Keep the ordinary ingest capacity at five entries rather than reducing
# CONFIG_FLASH_LOG_MAX_ENTRY_BYTES. Shrinking the entry size to 64 would cut the
# text payload to ~50 chars, which 60 of 213 log sites exceed -- including the
# crash post-mortems in main.c/errors.c and the DiveO2 broadcast-stranding
# warning, i.e. exactly the lines that are the only durable evidence of those
# faults. Queue depth trades burst tolerance instead, and a queue drop is COUNTED
# (drops_since_boot) where a text truncation is silent. Five ordinary slots cover the
# design basis in Kconfig.flash_log (one 64 KiB block erase, ~150-400 ms, at
# ~400 B/s peak ingest = under 2 slots).
# Five ordinary entries plus three slots reserved for boot/dive markers.
CONFIG_FLASH_LOG_QUEUE_DEPTH=8
```

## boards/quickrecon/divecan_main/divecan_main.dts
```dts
/*
 * QuickRecon DiveCAN MainPCB.
 *
 * The MainPCB shares the STM32L431, clocking, CAN, cell interfaces, ADCs and
 * internal OTA layout with DiveCAN Jr.  The board-specific differences below
 * replace SPI NOR with the native 1-bit SDMMC socket, describe the Rev2 power
 * mux, and correct the LEDs, solenoid output and hardware-version pattern.
 */
#include "../divecan_jr/divecan_jr.dts"

/* Remove Jr's SPI-NOR node and its fixed partitions before reusing the same
 * labels for MainPCB's raw SD flash device. */
/delete-node/ &spi_flash;

/ {
    model = "QuickRecon DiveCAN MainPCB";
    compatible = "quickrecon,divecan-main";

    leds {
        led_1: led_1 {
            gpios = <&gpiob 1 GPIO_ACTIVE_HIGH>;
        };
        led_2: led_2 {
            gpios = <&gpiob 2 GPIO_ACTIVE_HIGH>;
        };
        led_3: led_3 {
            gpios = <&gpiob 10 GPIO_ACTIVE_HIGH>;
        };
        led_4: led_4 {
            gpios = <&gpiob 11 GPIO_ACTIVE_HIGH>;
        };
        led_6: led_6 {
            gpios = <&gpiob 13 GPIO_ACTIVE_HIGH>;
        };
        led_7: led_7 {
            gpios = <&gpiob 14 GPIO_ACTIVE_HIGH>;
        };
    };

    /* The first 64 MiB of the SD card is firmware-owned raw storage.  Keeping
     * the existing partition labels and offsets means OTA, factory restore,
     * flash logging and NVS continue to use flash_area without a filesystem. */
    spi_flash: sd-flash {
        compatible = "quickrecon,sd-flash";
        disk-name = "SD";
        size = <DT_SIZE_M(64)>;
        erase-block-size = <4096>;
        write-block-size = <8>;
        status = "okay";

        partitions {
            compatible = "fixed-partitions";
            #address-cells = <1>;
            #size-cells = <1>;

            slot1_partition: partition@0 {
                label = "image-1";
                reg = <0x00000000 DT_SIZE_K(220)>;
            };
            scratch_partition: partition@37000 {
                label = "image-scratch";
                reg = <0x00037000 DT_SIZE_K(64)>;
            };
            factory_partition: partition@47000 {
                label = "factory-image";
                reg = <0x00047000 DT_SIZE_K(220)>;
            };
            log_telemetry_partition: partition@80000 {
                label = "log-telemetry";
                reg = <0x00080000 DT_SIZE_M(48)>;
            };
            log_text_partition: partition@3080000 {
                label = "log-text";
                reg = <0x03080000 DT_SIZE_M(8)>;
            };
            storage_partition: partition@3ff8000 {
                label = "storage";
                reg = <0x03ff8000 DT_SIZE_K(32)>;
            };
        };
    };
};

/* The included Jr definition places a W25Q512 under SPI2.  Those pins are
 * LEDs on MainPCB, so remove the child entirely before disabling the bus. */
&spi2 {
    status = "disabled";
};

/* MainPCB SD socket: PC12=CK, PD2=CMD, PC8=DAT0, PC6=active-low detect. */
&sdmmc1 {
    pinctrl-0 = <&sdmmc1_ck_pc12 &sdmmc1_cmd_pd2 &sdmmc1_d0_pc8>;
    pinctrl-names = "default";
    disk-name = "SD";
    bus-width = <1>;
    cd-gpios = <&gpioc 6 GPIO_ACTIVE_LOW>;
    status = "okay";
};

/* SDMMC1 uses HSI48 as its domain clock on STM32L431. */
&clk_hsi48 {
    status = "okay";
};

/* GPIO hogs are standard Zephyr board initialisation, not a storage or power
 * driver.  They make VBUS available before the SD disk initialises at priority
 * 90.  The application power driver subsequently owns and may reconfigure the
 * same pins according to CONFIG_POWER_MODE_* and drives 11 on shutdown. */
&gpioa {
    vbus_sel1_boot: vbus-sel1-boot {
        gpio-hog;
        gpios = <6 GPIO_ACTIVE_HIGH>;
        output-high;
    };

    vbus_sel2_boot: vbus-sel2-boot {
        gpio-hog;
        gpios = <5 GPIO_ACTIVE_HIGH>;
        output-low;
    };
};

/* Rev2.3/2.4: VER_DET_1 grounded, VER_DET_2/3 floating. */
&hw_version {
    expected-pattern = <0 2 2>;
};

/* MainPCB has one solenoid drive input on PC1.  PB4, PC11, PB5 and PA7 are
 * source-disable/status signals on this board rather than solenoid channels. */
&solenoids {
    gpios = <&gpioc 1 GPIO_ACTIVE_HIGH>;
};

/* VBUS is the output of the dual-source mux rather than PA1 directly. */
&vbus_reg {
    /delete-property/ enable-gpios;
    regulator-always-on;
};

&power {
    /delete-property/ vcc-sense;
    bus-select-gpios = <&gpioa 6 GPIO_ACTIVE_HIGH>,
                       <&gpioa 5 GPIO_ACTIVE_HIGH>;
    battery-enable-gpios = <&gpioa 1 GPIO_ACTIVE_LOW>;
    vcc-source-gpios = <&gpioa 4 GPIO_ACTIVE_HIGH>;
    vbus-source-gpios = <&gpioa 7 GPIO_ACTIVE_HIGH>;
    vbus-sense-io-channels = <&adc1 5>;
    vbus-divider-ratio = <11000>;
    can-sense-io-channels = <&adc1 3>;
    can-divider-ratio = <11000>;
};

/* MainPCB has dedicated VBUS/CAN ADC channels; the Jr VBAT sensor does not
 * represent either rail on this power topology. */
&vbat {
    status = "disabled";
};
```

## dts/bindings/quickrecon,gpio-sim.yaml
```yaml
description: |
  GPIO emulator with external drive simulation.

  Behaves identically to zephyr,gpio-emul except that pins marked as
  "externally driven" (via gpio_sim_drive()) preserve their value when
  the pin is reconfigured with GPIO_PULL_UP or GPIO_PULL_DOWN. This
  models real hardware where an external low-impedance connection
  (wired to ground or VCC) overcomes internal pull resistors.

compatible: "quickrecon,gpio-sim"

include: [gpio-controller.yaml, base.yaml]

properties:
  "#gpio-cells":
    const: 2

  ngpios:
    type: int
    description: Number of GPIOs

  rising-edge:
    type: boolean
    description: Rising edge interrupt support

  falling-edge:
    type: boolean
    description: Falling edge interrupt support

  high-level:
    type: boolean
    description: High level interrupt support

  low-level:
    type: boolean
    description: Low level interrupt support

gpio-cells:
  - pin
  - flags
```

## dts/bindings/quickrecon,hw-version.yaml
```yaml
description: |
  QuickRecon hardware version detection.

  Reads version detection pins at boot and compares against the expected
  pattern. If the pattern doesn't match, the system halts with a blink
  code on the LED to indicate a firmware/hardware mismatch.

  Each pin is read twice to distinguish three states:
    0 = wired to ground (reads LOW with both pull-up and pull-down)
    1 = wired to VCC / externally pulled up (reads HIGH with both)
    2 = floating / high-impedance (reads HIGH with pull-up, LOW with pull-down)

  Version table:
    Rev2.2: ver_det = [Z, Z, Z] → expected-pattern = [2, 2, 2]
    Rev2.3: ver_det = [0, Z, Z] → expected-pattern = [0, 2, 2]
    Rev2.4: ver_det = [0, Z, Z] → expected-pattern = [0, 2, 2]
    Jr:     ver_det = [0, 0, Z] → expected-pattern = [0, 0, 2]
    Jr2:    ver_det = [0, 0, 0] → expected-pattern = [0, 0, 0]

compatible: "quickrecon,hw-version"

# Standard properties (status, zephyr,deferred-init, ...) — required so test
# overlays can defer instances and initialise them under scripted GPIO state.
include: base.yaml

properties:
  detect-gpios:
    type: phandle-array
    required: true
    description: |
      Version detection GPIO pins, ordered [ver_det_1, ver_det_2, ver_det_3].

  expected-pattern:
    type: array
    required: true
    description: |
      Expected pin state for each detection pin:
        0 = wired to ground
        1 = wired to VCC / externally pulled high
        2 = floating (high impedance)

  error-led-gpios:
    type: phandle-array
    description: |
      LED to blink if version mismatch is detected.
```

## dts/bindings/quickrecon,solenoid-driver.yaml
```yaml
description: |
  Hardware-timed solenoid driver with deadman safety.

  Drives 1-4 solenoid outputs via GPIO with a hardware timer
  that guarantees all outputs are forced off after a configurable
  interval, regardless of application state.

  Example:

    solenoids {
        compatible = "quickrecon,solenoid-driver";
        gpios = <&gpiob 4 GPIO_ACTIVE_HIGH>,
                <&gpioc 11 GPIO_ACTIVE_HIGH>;
        counter = <&sol_timer>;
        max-on-time-us = <100000>;
    };

compatible: "quickrecon,solenoid-driver"

# Standard properties (status, zephyr,deferred-init, ...) — required so test
# overlays can defer instances whose dependencies (counter/GPIO) are
# themselves deferred, and drive the init failure arms via device_init().
include: base.yaml

properties:
  gpios:
    type: phandle-array
    required: true
    description: |
      GPIO specifiers for each solenoid output, in channel order.
      Between 1 and 4 entries.

  counter:
    type: phandle
    required: true
    description: |
      Hardware counter device used as the deadman timer.
      Must support at least one alarm channel. The counter
      ISR forces all solenoid GPIOs low when it fires.

  max-on-time-us:
    type: int
    required: true
    description: |
      Maximum allowed on-time in microseconds. Requests exceeding
      this value are clamped. Acts as a hard safety ceiling
      independent of application logic.
```

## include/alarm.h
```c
#ifndef DIVECAN_ALARM_H
#define DIVECAN_ALARM_H

#include <stdint.h>
#include <zephyr/zbus/zbus.h>

typedef uint32_t AlarmMask_t;

enum {
    ALARM_PPO2_LOW     = 1U << 0,
    ALARM_PPO2_HIGH    = 1U << 1,
    ALARM_PPO2_INVALID = 1U << 2,
    ALARM_PPO2_MASK    = ALARM_PPO2_LOW | ALARM_PPO2_HIGH | ALARM_PPO2_INVALID,
};

/* Alarm thresholds in centibar. The low threshold is normally 0.40 bar, but
 * drops to 0.16 bar while the 0.19 bar hypoxic-diluent setpoint is active so the
 * low alarm does not nuisance-fire across the diluent-PPO2 band (see alarm.c and
 * PPO2_SETPOINT_HYPOXIC_CB in runtime_settings.h). */
#define ALARM_PPO2_LOW_DEFAULT_CB 40U   /* 0.40 bar */
#define ALARM_PPO2_LOW_HYPOXIC_CB 16U   /* 0.16 bar (active at the 0.19 setpoint) */
#define ALARM_PPO2_HIGH_CB        160U  /* 1.60 bar */

ZBUS_CHAN_DECLARE(chan_alarm_state);

void alarm_update(AlarmMask_t owned_mask, AlarmMask_t active_mask);
AlarmMask_t alarm_ppo2_reasons(uint8_t consensus_ppo2, uint8_t confidence,
                               uint8_t setpoint_cb);

#endif
```

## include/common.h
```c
/**
 * @file common.h
 * @brief Project-wide numeric typedefs and bit-width constants.
 *
 * Provides domain-typed aliases for primitive types (satisfying SonarQube S813)
 * and shared shift/mask constants used across all modules.
 */
#ifndef COMMON_H
#define COMMON_H

#include <stdint.h>

/* ---- Generic numeric typedefs ----
 *
 * SonarQube S813 forbids bare `float`/`double`/`int` in interface positions.
 * These typedefs mirror the STM32 base (see ../../STM32/Core/Src/common.h)
 * so that domain meaning is encoded in the name and the underlying width
 * can be swapped centrally if needed.
 */

typedef float Numeric_t;                /**< Generic float for in-module math */
/** Full-precision PPO2 in bar (vs the centibar wire type).  Single-precision:
 *  the L431 FPU is single-only, so double math runs in softfloat.  PPO2 spans
 *  0-2.55 bar with centibar wire resolution; float's 2^-24 relative error is
 *  orders of magnitude inside both the sensor noise floor and the wire
 *  rounding.  Was double to mirror the legacy STM32 firmware. */
typedef float PrecisionPPO2_t;
typedef float Percent_t;                /**< Generic percentage (0-100) */
typedef float ADCV_t;                   /**< ADC voltage as a float */

typedef int Status_t;                   /**< Zephyr-style 0=success, <0=errno */
typedef int Index_t;                    /**< Loop/array index where signed is needed */

/* ---- Common bit-width constants ---- */

static const uint32_t BYTE_WIDTH = 8U;
static const uint32_t TWO_BYTE_WIDTH = 16U;
static const uint32_t THREE_BYTE_WIDTH = 24U;
static const uint8_t  BYTE_MASK = 0xFFU;

#endif /* COMMON_H */
```
